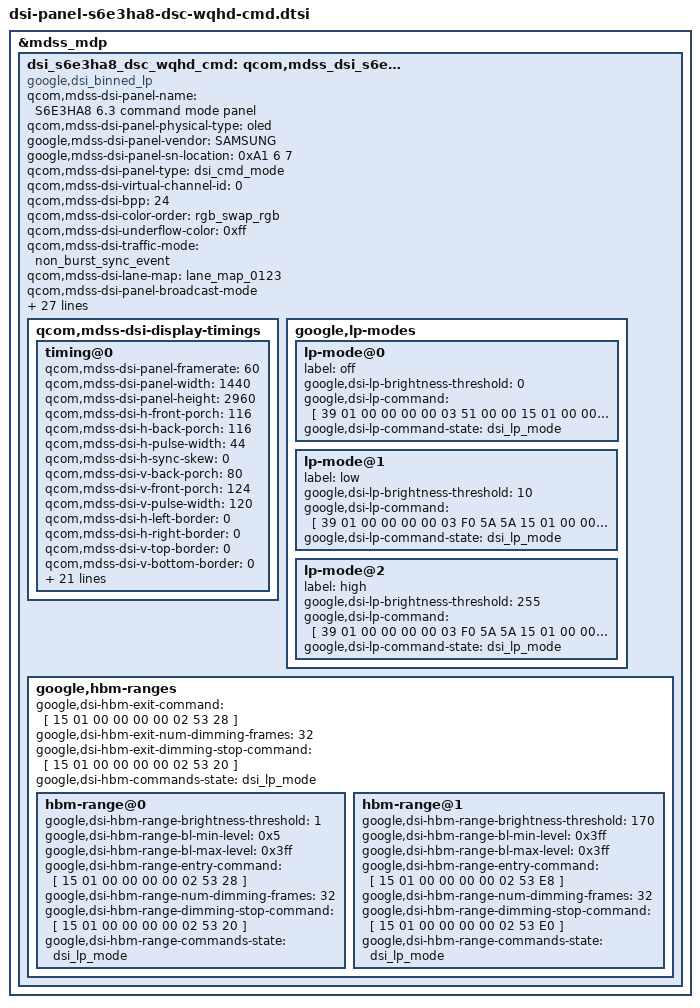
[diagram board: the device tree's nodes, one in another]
/* Copyright (c) 2017, The Linux Foundation. All rights reserved.
 *
 * This program is free software; you can redistribute it and/or modify
 * it under the terms of the GNU General Public License version 2 and
 * only version 2 as published by the Free Software Foundation.
 *
 * This program is distributed in the hope that it will be useful,
 * but WITHOUT ANY WARRANTY; without even the implied warranty of
 * MERCHANTABILITY or FITNESS FOR A PARTICULAR PURPOSE.  See the
 * GNU General Public License for more details.
 */

&mdss_mdp {
	dsi_s6e3ha8_dsc_wqhd_cmd: qcom,mdss_dsi_s6e3ha8 {
		compatible = "google,dsi_binned_lp";

		qcom,mdss-dsi-panel-name = "S6E3HA8 6.3 command mode panel";
		qcom,mdss-dsi-panel-physical-type = "oled";
		google,mdss-dsi-panel-vendor = "SAMSUNG";
		google,mdss-dsi-panel-sn-location = <0xA1 6 7>;
		qcom,mdss-dsi-panel-type = "dsi_cmd_mode";
		qcom,mdss-dsi-virtual-channel-id = <0>;
		qcom,mdss-dsi-bpp = <24>;
		qcom,mdss-dsi-color-order = "rgb_swap_rgb";
		qcom,mdss-dsi-underflow-color = <0xff>;
		qcom,mdss-dsi-traffic-mode = "non_burst_sync_event";
		qcom,mdss-dsi-lane-map = "lane_map_0123";
		qcom,mdss-dsi-panel-broadcast-mode;
		qcom,mdss-dsi-lane-0-state;
		qcom,mdss-dsi-lane-1-state;
		qcom,mdss-dsi-lane-2-state;
		qcom,mdss-dsi-lane-3-state;
		qcom,mdss-dsi-reset-sequence = <1 10>, <0 1>, <1 0>;

		qcom,mdss-dsi-bl-pmic-control-type = "bl_ctrl_dcs";
		qcom,mdss-dsi-bl-min-level = <0x5>;
		qcom,mdss-dsi-bl-max-level = <0x3ff>;
		qcom,mdss-dsi-panel-hdr-enabled;
		qcom,mdss-dsi-panel-hdr-color-primaries = <14500 15500 32000
			17000 15500 30000 8000 3000>;
		qcom,mdss-dsi-panel-peak-brightness = <5530000>;
		qcom,mdss-dsi-panel-blackness-level = <40>;

		qcom,mdss-dsi-dma-trigger = "trigger_sw";
		qcom,mdss-dsi-mdp-trigger = "none";
		qcom,mdss-dsi-wr-mem-start = <0x2c>;
		qcom,mdss-dsi-wr-mem-continue = <0x3c>;
		qcom,mdss-dsi-te-pin-select = <1>;
		qcom,mdss-dsi-te-dcs-command = <1>;

		qcom,mdss-dsi-te-check-enable;
		qcom,mdss-dsi-te-using-te-pin;
		/* qcom,esd-check-enabled; */
		qcom,mdss-dsi-panel-status-check-mode = "te_signal_check";

		qcom,mdss-dsi-init-delay-us = <5000>;

		qcom,mdss-pan-physical-width-dimension  = <70>;
		qcom,mdss-pan-physical-height-dimension = <144>;

		qcom,mdss-dsi-display-timings {
			timing@0 {
				qcom,mdss-dsi-panel-framerate = <60>;
				qcom,mdss-dsi-panel-width = <1440>;
				qcom,mdss-dsi-panel-height = <2960>;
				qcom,mdss-dsi-h-front-porch = <116>;
				qcom,mdss-dsi-h-back-porch = <116>;
				qcom,mdss-dsi-h-pulse-width = <44>;
				qcom,mdss-dsi-h-sync-skew = <0>;
				qcom,mdss-dsi-v-back-porch = <80>;
				qcom,mdss-dsi-v-front-porch = <124>;
				qcom,mdss-dsi-v-pulse-width = <120>;
				qcom,mdss-dsi-h-left-border = <0>;
				qcom,mdss-dsi-h-right-border = <0>;
				qcom,mdss-dsi-v-top-border = <0>;
				qcom,mdss-dsi-v-bottom-border = <0>;
				qcom,mdss-dsi-on-command = [
					07 01 00 00 00 00 01 01    /* Compression Enable */
					05 01 00 00 78 00 01 11    /* sleep out, Wait 120 ms */
					15 01 00 00 00 00 02 53 20 /* Write Control Display */
					05 01 00 00 00 00 02 35 00 /* TE on */
					39 01 00 00 00 00 03 F0 5A 5A /* Unlock */
					39 01 00 00 00 00 0A B9 01 B0 81 09 00 00 00 11 03 /* Sync display with touch */
					39 01 00 00 00 00 03 F0 A5 A5 /* Lock */
					05 01 00 00 00 00 01 29    /* display on */
				];
				qcom,mdss-dsi-on-command-state = "dsi_lp_mode";
				qcom,mdss-dsi-off-command = [
					05 01 00 00 0A 00 02 28 00 /* display off */
					05 01 00 00 78 00 02 10 00 /* sleep in */
				];

				qcom,mdss-dsi-vr-command = [
					39 01 00 00 00 00 03 F0 5A 5A
					15 01 00 00 00 00 02 B8 11
					39 01 00 00 00 00 05 B1 02 54 0C 00
					15 01 00 00 00 00 02 B0 07
					15 01 00 00 00 00 02 B1 07
					15 01 00 00 00 00 02 B0 10
					39 01 00 00 00 00 03 CB 03 0E
					15 01 00 00 00 00 02 B0 25
					15 01 00 00 00 00 02 CB 15
					15 01 00 00 00 00 02 B0 43
					15 01 00 00 00 00 02 CB 8F
					15 01 00 00 00 00 02 F7 03
					39 01 00 00 00 00 03 F0 A5 A5
					39 01 00 00 00 00 03 51 00 BB
					15 01 00 00 00 00 02 53 20
				];

				qcom,mdss-dsi-novr-command = [
					39 01 00 00 00 00 03 F0 5A 5A
					15 01 00 00 00 00 02 B8 15
					39 01 00 00 00 00 05 B1 00 0C 0C A0
					15 01 00 00 00 00 02 B0 08
					15 01 00 00 00 00 02 B1 0C
					15 01 00 00 00 00 02 B0 10
					39 01 00 00 00 00 03 CB 0B 06
					15 01 00 00 00 00 02 B0 25
					15 01 00 00 00 00 02 CB 09
					15 01 00 00 00 00 02 B0 43
					15 01 00 00 00 00 02 CB 0F
					15 01 00 00 14 00 02 F7 03
					39 01 00 00 00 00 03 F0 A5 A5
				];
				qcom,mdss-dsi-off-command-state = "dsi_hs_mode";

				qcom,mdss-dsi-nolp-command = [
					15 01 00 00 00 00 02 53 20
				];

				qcom,compression-mode = "dsc";
				qcom,mdss-dsc-slice-height = <40>;
				qcom,mdss-dsc-slice-width = <720>;
				qcom,mdss-dsc-slice-per-pkt = <1>;
				qcom,mdss-dsc-bit-per-component = <8>;
				qcom,mdss-dsc-bit-per-pixel = <8>;
				qcom,mdss-dsc-block-prediction-enable;

				/* 2xLM, 2xDSC Enc, 1xDSI Intf */
				qcom,display-topology = <2 2 1>;
				qcom,default-topology-index = <0>;
			};
		};

		google,lp-modes {
			lp-mode@0 {
				label = "off";

				google,dsi-lp-brightness-threshold = <0>;
				google,dsi-lp-command = [
					39 01 00 00 00 00 03 51 00 00 /* turn screen dark */
					15 01 00 00 00 00 02 53 20    /* disable HLPM */
				];
				google,dsi-lp-command-state = "dsi_lp_mode";
			};

			lp-mode@1 {
				label = "low";

				google,dsi-lp-brightness-threshold = <10>;
				google,dsi-lp-command = [
					39 01 00 00 00 00 03 F0 5A 5A /* Unlock */
					15 01 00 00 00 00 02 B0 05
					15 01 00 00 00 00 02 BB 84
					15 01 00 00 00 00 02 53 03
					15 01 00 00 00 00 02 F7 03
					39 01 00 00 00 00 03 F0 A5 A5 /* Lock */
				];
				google,dsi-lp-command-state = "dsi_lp_mode";
			};

			lp-mode@2 {
				label = "high";
				google,dsi-lp-brightness-threshold = <255>;
				google,dsi-lp-command = [
					39 01 00 00 00 00 03 F0 5A 5A /* Unlock */
					15 01 00 00 00 00 02 B0 05
					15 01 00 00 00 00 02 BB 04
					15 01 00 00 00 00 02 53 02
					15 01 00 00 00 00 02 F7 03
					39 01 00 00 00 00 03 F0 A5 A5 /* Lock */
				];
				google,dsi-lp-command-state = "dsi_lp_mode";
			};
		};

		google,hbm-ranges {
			google,dsi-hbm-exit-command = [
				/* Disable high brightness and enable
				 * brightness dimming
				 */
				15 01 00 00 00 00 02 53 28
			];
			google,dsi-hbm-exit-num-dimming-frames = <32>;
			google,dsi-hbm-exit-dimming-stop-command = [
				/* Disable high brightness and disable
				 * brightness dimming
				 */
				15 01 00 00 00 00 02 53 20
			];
			google,dsi-hbm-commands-state = "dsi_lp_mode";

			hbm-range@0 {
				google,dsi-hbm-range-brightness-threshold = <1>;

				google,dsi-hbm-range-bl-min-level = <0x5>;
				google,dsi-hbm-range-bl-max-level = <0x3ff>;
				google,dsi-hbm-range-entry-command = [
					/* Disable high brightness and enable
					 * brightness dimming
					 */
					15 01 00 00 00 00 02 53 28
				];
				google,dsi-hbm-range-num-dimming-frames = <32>;
				google,dsi-hbm-range-dimming-stop-command = [
					/* Disable high brightness and disable
					 * brightness dimming
					 */
					15 01 00 00 00 00 02 53 20
				];
				google,dsi-hbm-range-commands-state =
					"dsi_lp_mode";
			};

			hbm-range@1 {
				/* Normal brightness mode covers ~2 to 400
				 * nits, using panel brightness values up to
				 * 0x3ff. HBM extends the range to 600 nits,
				 * and remaps user brightness 1-255 to cover
				 * this extended range. In this extended range,
				 * 400 nits / 0x3ff corresponds to user
				 * brightness 170. Panel brightness is not
				 * adjustable in the 400-600 nit segment.
				 */
				google,dsi-hbm-range-brightness-threshold =
					<170>;

				google,dsi-hbm-range-bl-min-level = <0x3ff>;
				google,dsi-hbm-range-bl-max-level = <0x3ff>;

				google,dsi-hbm-range-entry-command = [
					/* Enable high brightness */
					15 01 00 00 00 00 02 53 E8
				];
				google,dsi-hbm-range-num-dimming-frames = <32>;
				google,dsi-hbm-range-dimming-stop-command = [
					/* Enable high brightness and disable
					 * brightness dimming
					 */
					15 01 00 00 00 00 02 53 E0
				];

				google,dsi-hbm-range-commands-state =
					"dsi_lp_mode";
			};
		};
	};
};
